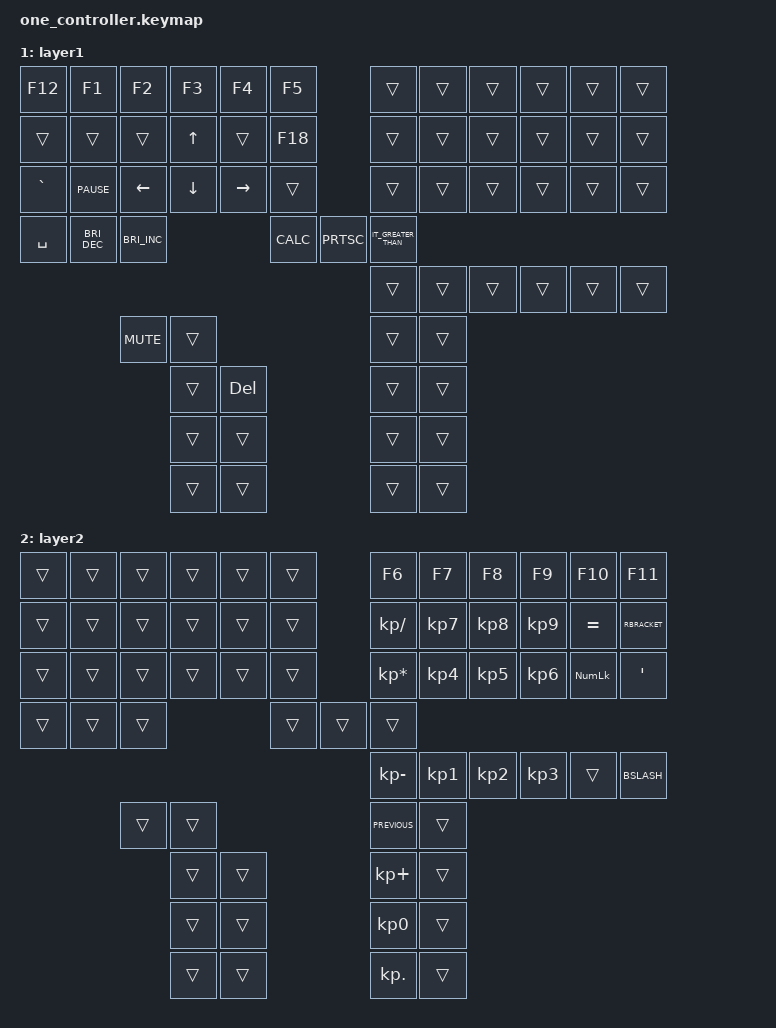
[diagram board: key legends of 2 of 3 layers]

  /*
  * Copyright (c) 2020 The ZMK Contributors
  *
  * SPDX-License-Identifier: MIT
  */

  #include <behaviors.dtsi>
  #include <dt-bindings/zmk/keys.h>
  #include <dt-bindings/zmk/bt.h>
  #include <dt-bindings/zmk/ext_power.h>
  #include "keys_it.h"

  / {
    keymap {
      compatible = "zmk,keymap";
  layer0 {
    bindings = <
        /* ┌─────────────── Left Hand ───────────────┐   ┌────────────── Right Hand ──────────────┐ */
           &kp ESCAPE  &kp N1  &kp N2  &kp N3  &kp N4  &kp N5        &kp N6  &kp N7  &kp N8  &kp N9  &kp N0  &kp MINUS
           &kp LALT    &kp Q   &kp W   &kp E   &kp R   &kp T         &kp Y   &kp U   &kp I   &kp O   &kp P   &kp LBRACKET
           &kp CAPS    &kp A   &kp S   &kp D   &kp F   &kp G         &kp H   &kp J   &kp K   &kp L   &kp SEMI &kp SQT
           &kp TAB     &kp Z   &kp X   &kp C   &kp V   &kp B         &kp N   &kp M   &kp COMMA &kp DOT &kp SLASH &kp BSLASH

        /* ┌──────────── Thumbs ────────────┐             ┌──────────── Thumbs ────────────┐ */
                           &kp C_VOL_DN &kp C_VOL_UP           &kp C_PLAY_PAUSE &kp C_NEXT
                                &kp LGUI &kp BSPC                 &kp SPACE &kp KP_ENTER
                                     &mo 1 &kp LALT               &kp LCTRL &kp LSHIFT
                                     &kp LCTRL                    &kp LSHIFT &mo 2
    >;
};
layer1 {
    bindings = <
        &kp F12  &kp F1  &kp F2  &kp F3  &kp F4  &kp F5         &trans &trans &trans &trans &trans &trans
        &trans   &trans  &trans  &kp UP  &trans  &kp F18        &trans &trans &trans &trans &trans &trans
        &kp GRAVE &kp PAUSE &kp LEFT &kp DOWN &kp RIGHT         &trans &trans &trans &trans &trans &trans &trans
        &kp SPACE &kp C_BRI_DEC &kp C_BRI_INC &kp C_CALC &kp PRTSC &kp IT_GREATER_THAN
                                                                &trans &trans &trans &trans &trans &trans

                           &kp C_MUTE &trans                    &trans &trans
                                &trans &kp DEL                 &trans &trans
                                     &trans &trans              &trans &trans
                                     &trans &trans              &trans &trans
    >;
};
layer2 {
    bindings = <
        &trans &trans &trans &trans &trans &trans        &kp F6  &kp F7  &kp F8  &kp F9  &kp F10 &kp F11
        &trans &trans &trans &trans &trans &trans        &kp KP_SLASH &kp KP_7 &kp KP_8 &kp KP_9 &kp EQUAL &kp RBRACKET
        &trans &trans &trans &trans &trans &trans        &kp KP_ASTERISK &kp KP_4 &kp KP_5 &kp KP_6 &kp NUMLOCK &kp SQT
        &trans &trans &trans &trans &trans &trans        &kp KP_MINUS &kp KP_1 &kp KP_2 &kp KP_3 &trans &kp BSLASH

                           &trans &trans                    &kp C_PREVIOUS &trans
                                &trans &trans               &kp KP_PLUS &trans
                                     &trans &trans          &kp KP_0 &trans
                                     &trans &trans          &kp KP_DOT &trans
    >;
};

    };
  };
  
